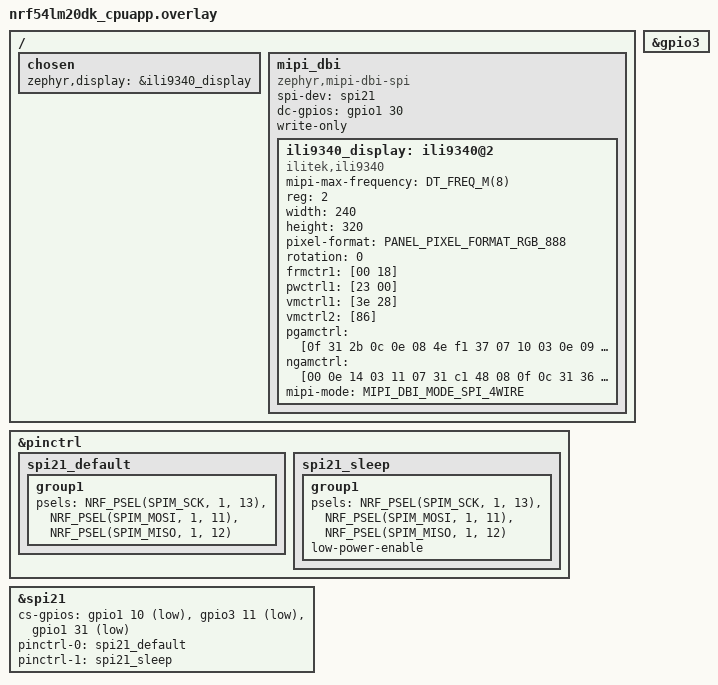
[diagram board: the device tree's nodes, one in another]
/*
 * Copyright (c) 2026 Nordic Semiconductor ASA
 *
 * SPDX-License-Identifier: LicenseRef-Nordic-5-Clause
 */

#include <zephyr/dt-bindings/display/panel.h>

&pinctrl {
	spi21_default: spi21_default {
		group1 {
			psels = <NRF_PSEL(SPIM_SCK, 1, 13)>,
			        <NRF_PSEL(SPIM_MOSI, 1, 11)>,
			        <NRF_PSEL(SPIM_MISO, 1, 12)>;
		};
	};

	spi21_sleep: spi21_sleep {
		group1 {
			psels = <NRF_PSEL(SPIM_SCK, 1, 13)>,
			        <NRF_PSEL(SPIM_MOSI, 1, 11)>,
			        <NRF_PSEL(SPIM_MISO, 1, 12)>;
			low-power-enable;
		};
	};
};

&spi21 {
	status = "okay";
	/* CS array: @0: NFC reader   @1: QM35 UWB module   @2: ILI9340 display */
	cs-gpios = <&gpio1 10 GPIO_ACTIVE_LOW>,
	           <&gpio3 11 GPIO_ACTIVE_LOW>,
	           <&gpio1 31 GPIO_ACTIVE_LOW>;
	pinctrl-0 = <&spi21_default>;
	pinctrl-1 = <&spi21_sleep>;
	pinctrl-names = "default", "sleep";
};

&gpio3 {
	status = "okay";
};

/ {
	chosen {
		zephyr,display = &ili9340_display;
	};

	mipi_dbi: mipi_dbi {
		compatible = "zephyr,mipi-dbi-spi";
		spi-dev = <&spi21>;
		dc-gpios = <&gpio1 30 GPIO_ACTIVE_HIGH>;
		write-only;
		#address-cells = <1>;
		#size-cells = <0>;

		ili9340_display: ili9340@2 {
			compatible = "ilitek,ili9340";
			mipi-max-frequency = <DT_FREQ_M(8)>;
			reg = <2>;
			width = <240>;
			height = <320>;
			pixel-format = <PANEL_PIXEL_FORMAT_RGB_888>;
			rotation = <0>;
			frmctr1 = [00 18];
			pwctrl1 = [23 00];
			vmctrl1 = [3e 28];
			vmctrl2 = [86];
			pgamctrl = [0f 31 2b 0c 0e 08 4e f1 37 07 10 03 0e 09 00];
			ngamctrl = [00 0e 14 03 11 07 31 c1 48 08 0f 0c 31 36 0f];
			mipi-mode = "MIPI_DBI_MODE_SPI_4WIRE";
		};
	};
};
